AUTOSAR XML (schema 4-3-0)
package /BMW/Platform/Darh/SwcImplementations
  swc implementation Darh_Implementation: behavior=InternalBehavior
    code-descriptors:
      code CodeDescriptor: artifact-descriptors=autosar-engineering-object={short-label=Default, category=SWSRC}
package /BMW/Platform/Darh/SwComponentTypes
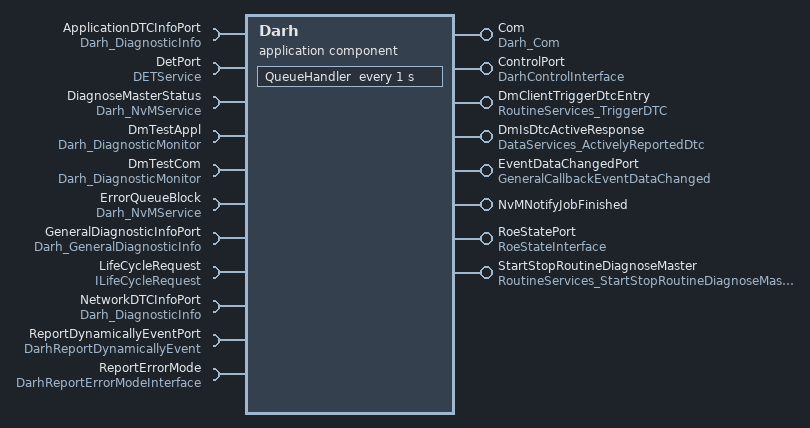
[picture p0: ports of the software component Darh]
  application sw component type Darh
    8 x provide port:
      Com: nonqueued-sender-com-spec=data-element=data, provided-interface=Darh_Com
      ControlPort: server-com-spec{operation=SetRoeSuspended, queue-length=1}, provided-interface=DarhControlInterface
      DmClientTriggerDtcEntry: server-com-spec{operation=Start, queue-length=1}, provided-interface=RoutineServices_TriggerDTC
      DmIsDtcActiveResponse: provided-interface=DataServices_ActivelyReportedDtc
        provided-com-specs:
          operation=ConditionCheckRead, queue-length=1
          operation=ReadData, queue-length=1
          operation=ReadDataLength, queue-length=1
      EventDataChangedPort: server-com-spec{operation=EventDataChanged, queue-length=1}, provided-interface=GeneralCallbackEventDataChanged
      NvMNotifyJobFinished: server-com-spec{operation=JobFinished, queue-length=1}, provided-interface=NvMNotifyJobFinished
      RoeStatePort: server-com-spec{operation=GetRoeState, queue-length=1}, provided-interface=RoeStateInterface
      StartStopRoutineDiagnoseMaster: provided-com-specs=[{operation=Start, queue-length=1}, {operation=Stop, queue-length=1}], provided-interface=RoutineServices_StartStopRoutineDiagnoseMaster
    provide/require port LifeCycle: mode-switch-sender-com-spec{enhanced-mode-api=true, mode-group=Mode, queue-length=2}, mode-switch-receiver-com-spec{enhanced-mode-api=true, supports-asynchronous-mode-switch=false}, provided-required-interface=ILifeCycle
    11 x require port:
      ApplicationDTCInfoPort: required-interface=Darh_DiagnosticInfo
      DetPort: required-interface=DETService
      DiagnoseMasterStatus: required-interface=Darh_NvMService
      DmTestAppl: required-interface=Darh_DiagnosticMonitor
      DmTestCom: required-interface=Darh_DiagnosticMonitor
      ErrorQueueBlock: required-interface=Darh_NvMService
      GeneralDiagnosticInfoPort: required-interface=Darh_GeneralDiagnosticInfo
      LifeCycleRequest: nonqueued-receiver-com-spec{data-element=requestMode, filter=data-filter-type=ALWAYS, init-value=DARH_STOPPED:2}, required-interface=ILifeCycleRequest
      NetworkDTCInfoPort: required-interface=Darh_DiagnosticInfo
      ReportDynamicallyEventPort: required-interface=DarhReportDynamicallyEvent
      ReportErrorMode: required-interface=DarhReportErrorModeInterface
    behavior InternalBehavior: data-type-mapping=[Darh_ModeRequestTypeMappings, Dcm_ModeRequestTypeMappings], included-data-type-set=data-type=[Darh_RoeStateType, Darh_SuspendedStateType]
      exclusive area ExclusiveArea_0
      operation invoked event OperationInvokedEvent_ConditionCheckReadActivelyReportedDtc: start-on-event=ConditionCheckReadActivelyReportedDtc, operation=DmIsDtcActiveResponse.ConditionCheckRead
      operation invoked event OperationInvokedEvent_EventDataChanged: start-on-event=EventDataChanged, operation=EventDataChangedPort.EventDataChanged
      operation invoked event OperationInvokedEvent_GetRoeState: start-on-event=GetRoeState, operation=RoeStatePort.GetRoeState
      data received event LifeCycleRequest: start-on-event=LifeCycleHandler, data=LifeCycleRequest.requestMode
      timing event TimingEvent: disabled-mode=[LifeCycle.Mode.DARH_INITIALIZED, LifeCycle.Mode.DARH_STOPPED], start-on-event=QueueHandler, period=1
      7 x operation invoked event:
        OperationInvokedEvent_ReadActivelyReportedDtc: start-on-event=ReadActivelyReportedDtc, operation=DmIsDtcActiveResponse.ReadData
        OperationInvokedEvent_ReadActivelyReportedDtcLength: start-on-event=ReadActivelyReportedDtcLength, operation=DmIsDtcActiveResponse.ReadDataLength
        OperationInvokedEvent_SetRoeSuspended: start-on-event=SetRoeSuspended, operation=ControlPort.SetRoeSuspended
        OperationInvokedEvent_StartRoutineDiagnoseMaster: start-on-event=StartRoutineDiagnoseMaster, operation=StartStopRoutineDiagnoseMaster.Start
        OperationInvokedEvent_StartRoutineTriggerDtc: start-on-event=StartRoutineTriggerDtc, operation=DmClientTriggerDtcEntry.Start
        OperationInvokedEvent_StopRoutineDiagnoseMaster: start-on-event=StopRoutineDiagnoseMaster, operation=StartStopRoutineDiagnoseMaster.Stop
        E_WriteDataBlockNotification: start-on-event=WriteDataBlockNotification, operation=NvMNotifyJobFinished.JobFinished
      port-api-options:
        enable-take-address=false, error-handling=NO-TRANSFORMER-ERROR-HANDLING, indirect-api=false, port=ApplicationDTCInfoPort
        enable-take-address=false, error-handling=NO-TRANSFORMER-ERROR-HANDLING, indirect-api=false, port=ControlPort
        enable-take-address=false, error-handling=NO-TRANSFORMER-ERROR-HANDLING, indirect-api=false, port=DetPort
        enable-take-address=false, error-handling=NO-TRANSFORMER-ERROR-HANDLING, indirect-api=false, port=DmClientTriggerDtcEntry
        enable-take-address=false, error-handling=NO-TRANSFORMER-ERROR-HANDLING, indirect-api=false, port=DmIsDtcActiveResponse
        enable-take-address=false, error-handling=NO-TRANSFORMER-ERROR-HANDLING, indirect-api=false, port=DmTestAppl
        enable-take-address=false, error-handling=NO-TRANSFORMER-ERROR-HANDLING, indirect-api=false, port=DmTestCom
        enable-take-address=false, error-handling=NO-TRANSFORMER-ERROR-HANDLING, indirect-api=false, port=EventDataChangedPort
        enable-take-address=false, error-handling=NO-TRANSFORMER-ERROR-HANDLING, indirect-api=false, port=GeneralDiagnosticInfoPort
        enable-take-address=false, error-handling=NO-TRANSFORMER-ERROR-HANDLING, indirect-api=false, port=LifeCycle
        enable-take-address=false, error-handling=NO-TRANSFORMER-ERROR-HANDLING, indirect-api=false, port=LifeCycleRequest
        enable-take-address=false, error-handling=NO-TRANSFORMER-ERROR-HANDLING, indirect-api=false, port=NetworkDTCInfoPort
        enable-take-address=false, error-handling=NO-TRANSFORMER-ERROR-HANDLING, indirect-api=false, port=ReportDynamicallyEventPort
        enable-take-address=false, error-handling=NO-TRANSFORMER-ERROR-HANDLING, indirect-api=false, port=ReportErrorMode
        enable-take-address=false, error-handling=NO-TRANSFORMER-ERROR-HANDLING, indirect-api=false, port=RoeStatePort
      15 x runnable:
        ConditionCheckRead: can-be-invoked-concurrently=true, mode-access-point=LifeCycle.Mode, symbol=Darh_ConditionCheckReadErrorQueueHandler
          sync call DetPort_ReportError: operation=DetPort.ReportError, timeout=0
        ConditionCheckReadActivelyReportedDtc: can-be-invoked-concurrently=true, mode-access-point=LifeCycle.Mode, symbol=Darh_ConditionCheckReadActivelyReportedDtcHandler
          sync call DetPort_ReportError: operation=DetPort.ReportError, timeout=0
        EventDataChanged: can-enter-exclusive-area=ExclusiveArea_0, symbol=Darh_EventDataChangedHandler
          4 x sync call, all with timeout=0:
            DetPort_ReportError: operation=DetPort.ReportError
            ErrorQueueBlock_SetRamBlockStatus: operation=ErrorQueueBlock.SetRamBlockStatus
            GeneralDiag_GetFreezeFrameData: operation=GeneralDiagnosticInfoPort.GetEventFreezeFrameData
            ReportDynamicallyEventPort_EventToReport: operation=ReportDynamicallyEventPort.EventToReport
        GetRoeState: can-enter-exclusive-area=ExclusiveArea_0, can-be-invoked-concurrently=true, symbol=Darh_ReadRoeStateDataHandler
          sync call DetPort_ReportError: operation=DetPort.ReportError, timeout=0
        LifeCycleHandler: can-enter-exclusive-area=ExclusiveArea_0, mode-access-point=LifeCycle.Mode, symbol=Darh_LifeCycleHandler
          data-read-access:
            access dra_ILifeCycleRequest_requestMode: accessed-variable=LifeCycleRequest.requestMode
          mode switch point LifeCycle: mode-group=LifeCycle.Mode
        QueueHandler: can-enter-exclusive-area=ExclusiveArea_0, symbol=Darh_ErrorQueueHandler
          data-send-points:
            access Com: accessed-variable=Com.data
          sync call DetPort_ReportError: operation=DetPort.ReportError, timeout=0
        ReadActivelyReportedDtc: symbol=Darh_ReadActivelyReportedDtcDataHandler
          5 x sync call, all with timeout=0:
            DetPort_ReportError: operation=DetPort.ReportError
            GeneralDiag_GetDTCOfEvent: operation=GeneralDiagnosticInfoPort.GetDTCOfEvent
            ReportDynamicallyEventPort_EventIdx2EventId: operation=ReportDynamicallyEventPort.EventIdx2EventId
            ReportDynamicallyEventPort_EventToReport: operation=ReportDynamicallyEventPort.EventToReport
            ReportDynamicallyEventPort_EventToReportCount: operation=ReportDynamicallyEventPort.EventToReportCount
        ReadActivelyReportedDtcLength: symbol=Darh_ReadActivelyReportedDtcLengthHandler
          sync call DetPort_ReportError: operation=DetPort.ReportError, timeout=0
          sync call ReportDynamicallyEventPort_EventToReportCount: operation=ReportDynamicallyEventPort.EventToReportCount, timeout=0
        ReadErrorQueue: can-enter-exclusive-area=ExclusiveArea_0, symbol=Darh_ReadErrorQueueDataHandler
          sync call DetPort_ReportError: operation=DetPort.ReportError, timeout=0
          sync call GeneralDiag_GetDTCOfEvent: operation=GeneralDiagnosticInfoPort.GetDTCOfEvent, timeout=0
        ReadErrorQueueLength: can-enter-exclusive-area=ExclusiveArea_0, symbol=Darh_ReadErrorQueueLengthHandler
          sync call DetPort_ReportError: operation=DetPort.ReportError, timeout=0
        SetRoeSuspended: can-be-invoked-concurrently=true, symbol=Darh_SetRoeSuspendedHandler
          sync call DetPort_ReportError: operation=DetPort.ReportError, timeout=0
        StartRoutineDiagnoseMaster: symbol=Darh_StartRoutineDiagnoseMasterHandler
          sync call DiagnoseMasterStatus_WriteBlock: operation=DiagnoseMasterStatus.WriteBlock, timeout=0
        StartRoutineTriggerDtc: symbol=Darh_StartRoutineTriggerDtcHandler
          5 x sync call, all with timeout=0:
            ApplicationDTC_GetDTCOfEvent: operation=ApplicationDTCInfoPort.GetDTCOfEvent
            ApplicationDTC_GetEvtStatus: operation=DmTestAppl.SetEventStatus
            DetPort_ReportError: operation=DetPort.ReportError
            DmTestCom_SetEventStatus: operation=DmTestCom.SetEventStatus
            NetworkDTCInfo_GetDTCOfEvent: operation=NetworkDTCInfoPort.GetDTCOfEvent
        StopRoutineDiagnoseMaster: symbol=Darh_StopRoutineDiagnoseMasterHandler
          sync call DiagnoseMasterStatus_WriteBlock: operation=DiagnoseMasterStatus.WriteBlock, timeout=0
        WriteDataBlockNotification: can-be-invoked-concurrently=true, symbol=Darh_NvMNotifyJobFinishedDiagnoseMasterStatus
      6 x swc service dependency:
        DarhDcmServiceNeeds
          assigned-ports:
            port-prototype=StartStopRoutineDiagnoseMaster, role=RoutineServices
            port-prototype=DmClientTriggerDtcEntry, role=RoutineServices
            port-prototype=DmIsDtcActiveResponse, role=DataServices
          service-needs:
            diagnostic communication manager needs sn_DarhDcmServiceNeeds
        DarhDummyApplicationDtcServiceNeeds
          assigned-ports:
            port-prototype=ApplicationDTCInfoPort, role=DiagnosticInfo
            port-prototype=DmTestAppl, role=Darh_DiagnosticMonitor
          service-needs:
            diagnostic event needs sn_DarhApplicationDtcServiceNeeds: consider-pto-status=false, dtc-kind=NON-EMMISSION-RELATED-DTC  # DTC vale shall be set to: 0x02FF00 + ECUDiagnosticAddress Event destination: primary origin Event kind: DEM_EVENT_KIND_SWC Description: Dummy Application DTC
        DarhDummyNetworkDtcServiceNeeds
          assigned-ports:
            port-prototype=NetworkDTCInfoPort, role=DiagnosticInfo
            port-prototype=DmTestCom, role=Darh_DiagnosticMonitor
          service-needs:
            diagnostic event needs sn_DarhDtcServiceNeeds: consider-pto-status=false, dtc-kind=NON-EMMISSION-RELATED-DTC  # DTC vale shall be set to: 0xC90400 + (0x4000 * ECUDiagnosticAddress) + 0x07FF Event destination: primary origin Event kind: DEM_EVENT_KIND_SWC Description: Dummy Network DTC
        DarhNvmAddressServiceNeed: assigned-ports=role-based-port-assignment={port-prototype=DiagnoseMasterStatus, role=NvMService}
          service-needs:
            nv block needs sn_DarhNvmAddressServiceNeed: n-data-sets=1, restore-at-start=true, store-at-shutdown=false
        DarhNvmServiceNeed: assigned-ports=role-based-port-assignment={port-prototype=ErrorQueueBlock, role=NvMService}
          service-needs:
            nv block needs sn_DarhNvmServiceNeed: n-data-sets=1, restore-at-start=true, store-at-shutdown=true
        DemServiceNeeds
          assigned-ports:
            port-prototype=EventDataChangedPort, role=GeneralCallbackEventDataChanged
            port-prototype=GeneralDiagnosticInfoPort, role=GeneralDiagnosticInfo
          service-needs:
            diagnostic event manager needs sn_DemServiceNeeds
